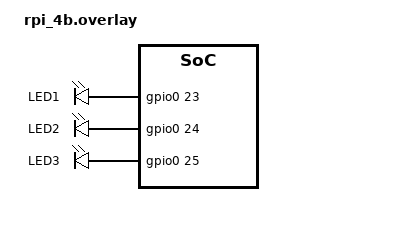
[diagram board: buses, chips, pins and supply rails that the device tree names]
/ {
    aliases {
        led1 = &led_1;
        led2 = &led_2;
        led3 = &led_3;
    };

    leds {
        led_1: led-1 {
            gpios = <&gpio0 23 GPIO_ACTIVE_HIGH>; /* GPIO 23 */
            label = "LED1";
        };
        led_2: led-2 {
            gpios = <&gpio0 24 GPIO_ACTIVE_HIGH>; /* GPIO 24 */
            label = "LED2";
        };
        led_3: led-3 {
            gpios = <&gpio0 25 GPIO_ACTIVE_HIGH>; /* GPIO 25 */
            label = "LED3";
        };
    };
};

&gpio0 {
	status = "okay";
};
